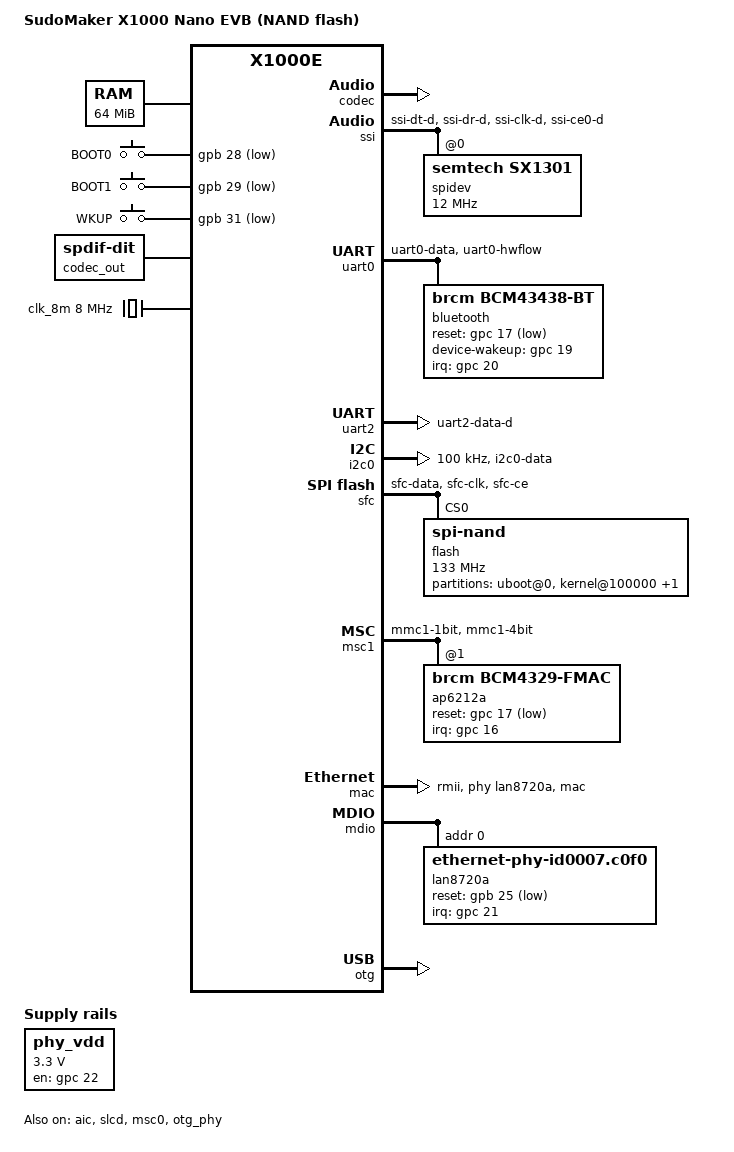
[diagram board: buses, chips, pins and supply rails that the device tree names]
// SPDX-License-Identifier: GPL-2.0
/dts-v1/;

#include "x1000.dtsi"
#include <dt-bindings/gpio/gpio.h>
#include <dt-bindings/input/input.h>
#include <dt-bindings/clock/ingenic,sysost.h>
#include <dt-bindings/interrupt-controller/irq.h>

/ {
	compatible = "sudomaker,x1000-nano-evb", "ingenic,x1000e";
	model = "SudoMaker X1000 Nano EVB (NAND flash)";

	aliases {
		serial2 = &uart2;
	};

	chosen {
		stdout-path = "serial2:115200n8";
	};

	memory {
		device_type = "memory";
		reg = <0x0 0x04000000>;
	};

	gpio_keys {
		compatible = "gpio-keys";

		btn_lf {
			wakeup-source;
			label = "BOOT0";
			linux,code = <KEY_F1>;
			gpios = <&gpb 28 GPIO_ACTIVE_LOW>;
		};

		btn_rf {
			wakeup-source;
			label = "BOOT1";
			linux,code = <KEY_F2>;
			gpios = <&gpb 29 GPIO_ACTIVE_LOW>;
		};

		btn_wkup {
			wakeup-source;
			label = "WKUP";
			linux,code = <KEY_F3>;
			gpios = <&gpb 31 GPIO_ACTIVE_LOW>;
		};
	};

	phy_vdd: regulator-phy_vdd {
				compatible = "regulator-fixed";

				regulator-name = "phy_vdd";
				regulator-min-microvolt = <3300000>;
				regulator-max-microvolt = <3300000>;

				gpio = <&gpc 22 GPIO_ACTIVE_HIGH>;
				enable-active-high;
				regulator-always-on;
	};

	sound {
		compatible = "simple-audio-card";

		simple-audio-card,name = "x1000-aic";

		status = "okay";

		simple-audio-card,bitclock-master = <&dai_codec>;
		simple-audio-card,frame-master = <&dai_codec>;

		simple-audio-card,format = "i2s";

		dai_cpu: simple-audio-card,cpu {
			sound-dai = <&aic>;
			system-clock-frequency = <24000000>;
			system-clock-direction-out;
		};

		dai_codec: simple-audio-card,codec {
			sound-dai = <&codec>;
			system-clock-frequency = <24000000>;
		};
	};

	codec_out: i2s-generic {
				#address-cells = <0>;
				#size-cells = <0>;
				#sound-dai-cells = <0>;
				compatible = "linux,spdif-dit";
				status = "okay";
	};

	clk_8m: clock {
		compatible = "fixed-clock";
		#clock-cells = <0>;
		clock-frequency = <8000000>;
		clock-accuracy = <100>;
	};
};

&exclk {
	clock-frequency = <24000000>;
};

&cgu {
	assigned-clocks = <&cgu X1000_CLK_SSIMUX>, <&cgu X1000_CLK_RTC>;
	assigned-clock-parents = <&cgu X1000_CLK_SSIPLL_DIV2>, <&cgu X1000_CLK_EXCLK_DIV512>;
};

&ost {
	/* 1500 kHz for the system timer and clocksource */
	assigned-clocks = <&ost OST_CLK_EVENT_TIMER>, <&ost OST_CLK_GLOBAL_TIMER>;
	assigned-clock-rates = <1500000>, <1500000>;
};

&aic {
	status = "okay";
	pinctrl-names = "default";
	pinctrl-0 = <&pins_i2s>;

	use-internal-codec;
};

&codec {
	status = "okay";
};

&slcd {
	status = "okay";

	pinctrl-names = "default";
	pinctrl-0 = <&pins_slcd>;

	reset-gpios = <&gpc 25 GPIO_ACTIVE_LOW>;
	rd-gpios = <&gpb 16 GPIO_ACTIVE_LOW>;

	width = <480>;
	height = <800>;
	buswidth = <8>;
	bpp = <24>;
	bus-max-speed = <50000000>;

	sequence-format = <1>; // NT35510: 16bit to 2x8bit, big endian

	init-sequence = /bits/ 16 <
		1 0xf000 2 0x0055
		1 0xf001 2 0x00aa
		1 0xf002 2 0x0052
		1 0xf003 2 0x0008
		1 0xf004 2 0x0001

		1 0xbc01 2 0x0086
		1 0xbc02 2 0x006a
		1 0xbd01 2 0x0086
		1 0xbd02 2 0x006a
		1 0xbe01 2 0x0067

		1 0xd100 2 0x0000
		1 0xd101 2 0x005d
		1 0xd102 2 0x0000
		1 0xd103 2 0x006b
		1 0xd104 2 0x0000
		1 0xd105 2 0x0084
		1 0xd106 2 0x0000
		1 0xd107 2 0x009c
		1 0xd108 2 0x0000
		1 0xd109 2 0x00b1
		1 0xd10a 2 0x0000
		1 0xd10b 2 0x00d9
		1 0xd10c 2 0x0000
		1 0xd10d 2 0x00fd
		1 0xd10e 2 0x0001
		1 0xd10f 2 0x0038
		1 0xd110 2 0x0001
		1 0xd111 2 0x0068
		1 0xd112 2 0x0001
		1 0xd113 2 0x00b9
		1 0xd114 2 0x0001
		1 0xd115 2 0x00fb
		1 0xd116 2 0x0002
		1 0xd117 2 0x0063
		1 0xd118 2 0x0002
		1 0xd119 2 0x00b9
		1 0xd11a 2 0x0002
		1 0xd11b 2 0x00bb
		1 0xd11c 2 0x0003
		1 0xd11d 2 0x0003
		1 0xd11e 2 0x0003
		1 0xd11f 2 0x0046
		1 0xd120 2 0x0003
		1 0xd121 2 0x0069
		1 0xd122 2 0x0003
		1 0xd123 2 0x008f
		1 0xd124 2 0x0003
		1 0xd125 2 0x00a4
		1 0xd126 2 0x0003
		1 0xd127 2 0x00b9
		1 0xd128 2 0x0003
		1 0xd129 2 0x00c7
		1 0xd12a 2 0x0003
		1 0xd12b 2 0x00c9
		1 0xd12c 2 0x0003
		1 0xd12d 2 0x00cb
		1 0xd12e 2 0x0003
		1 0xd12f 2 0x00cb
		1 0xd130 2 0x0003
		1 0xd131 2 0x00cb
		1 0xd132 2 0x0003
		1 0xd133 2 0x00cc

		1 0xd200 2 0x0000
		1 0xd201 2 0x005d
		1 0xd202 2 0x0000
		1 0xd203 2 0x006b
		1 0xd204 2 0x0000
		1 0xd205 2 0x0084
		1 0xd206 2 0x0000
		1 0xd207 2 0x009c
		1 0xd208 2 0x0000
		1 0xd209 2 0x00b1
		1 0xd20a 2 0x0000
		1 0xd20b 2 0x00d9
		1 0xd20c 2 0x0000
		1 0xd20d 2 0x00fd
		1 0xd20e 2 0x0001
		1 0xd20f 2 0x0038
		1 0xd210 2 0x0001
		1 0xd211 2 0x0068
		1 0xd212 2 0x0001
		1 0xd213 2 0x00b9
		1 0xd214 2 0x0001
		1 0xd215 2 0x00fb
		1 0xd216 2 0x0002
		1 0xd217 2 0x0063
		1 0xd218 2 0x0002
		1 0xd219 2 0x00b9
		1 0xd21a 2 0x0002
		1 0xd21b 2 0x00bb
		1 0xd21c 2 0x0003
		1 0xd21d 2 0x0003
		1 0xd21e 2 0x0003
		1 0xd21f 2 0x0046
		1 0xd220 2 0x0003
		1 0xd221 2 0x0069
		1 0xd222 2 0x0003
		1 0xd223 2 0x008f
		1 0xd224 2 0x0003
		1 0xd225 2 0x00a4
		1 0xd226 2 0x0003
		1 0xd227 2 0x00b9
		1 0xd228 2 0x0003
		1 0xd229 2 0x00c7
		1 0xd22a 2 0x0003
		1 0xd22b 2 0x00c9
		1 0xd22c 2 0x0003
		1 0xd22d 2 0x00cb
		1 0xd22e 2 0x0003
		1 0xd22f 2 0x00cb
		1 0xd230 2 0x0003
		1 0xd231 2 0x00cb
		1 0xd232 2 0x0003
		1 0xd233 2 0x00cc

		1 0xd300 2 0x0000
		1 0xd301 2 0x005d
		1 0xd302 2 0x0000
		1 0xd303 2 0x006b
		1 0xd304 2 0x0000
		1 0xd305 2 0x0084
		1 0xd306 2 0x0000
		1 0xd307 2 0x009c
		1 0xd308 2 0x0000
		1 0xd309 2 0x00b1
		1 0xd30a 2 0x0000
		1 0xd30b 2 0x00d9
		1 0xd30c 2 0x0000
		1 0xd30d 2 0x00fd
		1 0xd30e 2 0x0001
		1 0xd30f 2 0x0038
		1 0xd310 2 0x0001
		1 0xd311 2 0x0068
		1 0xd312 2 0x0001
		1 0xd313 2 0x00b9
		1 0xd314 2 0x0001
		1 0xd315 2 0x00fb
		1 0xd316 2 0x0002
		1 0xd317 2 0x0063
		1 0xd318 2 0x0002
		1 0xd319 2 0x00b9
		1 0xd31a 2 0x0002
		1 0xd31b 2 0x00bb
		1 0xd31c 2 0x0003
		1 0xd31d 2 0x0003
		1 0xd31e 2 0x0003
		1 0xd31f 2 0x0046
		1 0xd320 2 0x0003
		1 0xd321 2 0x0069
		1 0xd322 2 0x0003
		1 0xd323 2 0x008f
		1 0xd324 2 0x0003
		1 0xd325 2 0x00a4
		1 0xd326 2 0x0003
		1 0xd327 2 0x00b9
		1 0xd328 2 0x0003
		1 0xd329 2 0x00c7
		1 0xd32a 2 0x0003
		1 0xd32b 2 0x00c9
		1 0xd32c 2 0x0003
		1 0xd32d 2 0x00cb
		1 0xd32e 2 0x0003
		1 0xd32f 2 0x00cb
		1 0xd330 2 0x0003
		1 0xd331 2 0x00cb
		1 0xd332 2 0x0003
		1 0xd333 2 0x00cc

		1 0xd400 2 0x0000
		1 0xd401 2 0x005d
		1 0xd402 2 0x0000
		1 0xd403 2 0x006b
		1 0xd404 2 0x0000
		1 0xd405 2 0x0084
		1 0xd406 2 0x0000
		1 0xd407 2 0x009c
		1 0xd408 2 0x0000
		1 0xd409 2 0x00b1
		1 0xd40a 2 0x0000
		1 0xd40b 2 0x00d9
		1 0xd40c 2 0x0000
		1 0xd40d 2 0x00fd
		1 0xd40e 2 0x0001
		1 0xd40f 2 0x0038
		1 0xd410 2 0x0001
		1 0xd411 2 0x0068
		1 0xd412 2 0x0001
		1 0xd413 2 0x00b9
		1 0xd414 2 0x0001
		1 0xd415 2 0x00fb
		1 0xd416 2 0x0002
		1 0xd417 2 0x0063
		1 0xd418 2 0x0002
		1 0xd419 2 0x00b9
		1 0xd41a 2 0x0002
		1 0xd41b 2 0x00bb
		1 0xd41c 2 0x0003
		1 0xd41d 2 0x0003
		1 0xd41e 2 0x0003
		1 0xd41f 2 0x0046
		1 0xd420 2 0x0003
		1 0xd421 2 0x0069
		1 0xd422 2 0x0003
		1 0xd423 2 0x008f
		1 0xd424 2 0x0003
		1 0xd425 2 0x00a4
		1 0xd426 2 0x0003
		1 0xd427 2 0x00b9
		1 0xd428 2 0x0003
		1 0xd429 2 0x00c7
		1 0xd42a 2 0x0003
		1 0xd42b 2 0x00c9
		1 0xd42c 2 0x0003
		1 0xd42d 2 0x00cb
		1 0xd42e 2 0x0003
		1 0xd42f 2 0x00cb
		1 0xd430 2 0x0003
		1 0xd431 2 0x00cb
		1 0xd432 2 0x0003
		1 0xd433 2 0x00cc

		1 0xd500 2 0x0000
		1 0xd501 2 0x005d
		1 0xd502 2 0x0000
		1 0xd503 2 0x006b
		1 0xd504 2 0x0000
		1 0xd505 2 0x0084
		1 0xd506 2 0x0000
		1 0xd507 2 0x009c
		1 0xd508 2 0x0000
		1 0xd509 2 0x00b1
		1 0xd50a 2 0x0000
		1 0xd50b 2 0x00D9
		1 0xd50c 2 0x0000
		1 0xd50d 2 0x00fd
		1 0xd50e 2 0x0001
		1 0xd50f 2 0x0038
		1 0xd510 2 0x0001
		1 0xd511 2 0x0068
		1 0xd512 2 0x0001
		1 0xd513 2 0x00b9
		1 0xd514 2 0x0001
		1 0xd515 2 0x00fb
		1 0xd516 2 0x0002
		1 0xd517 2 0x0063
		1 0xd518 2 0x0002
		1 0xd519 2 0x00b9
		1 0xd51a 2 0x0002
		1 0xd51b 2 0x00bb
		1 0xd51c 2 0x0003
		1 0xd51d 2 0x0003
		1 0xd51e 2 0x0003
		1 0xd51f 2 0x0046
		1 0xd520 2 0x0003
		1 0xd521 2 0x0069
		1 0xd522 2 0x0003
		1 0xd523 2 0x008f
		1 0xd524 2 0x0003
		1 0xd525 2 0x00a4
		1 0xd526 2 0x0003
		1 0xd527 2 0x00b9
		1 0xd528 2 0x0003
		1 0xd529 2 0x00c7
		1 0xd52a 2 0x0003
		1 0xd52b 2 0x00c9
		1 0xd52c 2 0x0003
		1 0xd52d 2 0x00cb
		1 0xd52e 2 0x0003
		1 0xd52f 2 0x00cb
		1 0xd530 2 0x0003
		1 0xd531 2 0x00cb
		1 0xd532 2 0x0003
		1 0xd533 2 0x00cc

		1 0xd600 2 0x0000
		1 0xd601 2 0x005d
		1 0xd602 2 0x0000
		1 0xd603 2 0x006b
		1 0xd604 2 0x0000
		1 0xd605 2 0x0084
		1 0xd606 2 0x0000
		1 0xd607 2 0x009c
		1 0xd608 2 0x0000
		1 0xd609 2 0x00b1
		1 0xd60a 2 0x0000
		1 0xd60b 2 0x00d9
		1 0xd60c 2 0x0000
		1 0xd60d 2 0x00fd
		1 0xd60e 2 0x0001
		1 0xd60f 2 0x0038
		1 0xd610 2 0x0001
		1 0xd611 2 0x0068
		1 0xd612 2 0x0001
		1 0xd613 2 0x00b9
		1 0xd614 2 0x0001
		1 0xd615 2 0x00fb
		1 0xd616 2 0x0002
		1 0xd617 2 0x0063
		1 0xd618 2 0x0002
		1 0xd619 2 0x00b9
		1 0xd61a 2 0x0002
		1 0xd61b 2 0x00bb
		1 0xd61c 2 0x0003
		1 0xd61d 2 0x0003
		1 0xd61e 2 0x0003
		1 0xd61f 2 0x0046
		1 0xd620 2 0x0003
		1 0xd621 2 0x0069
		1 0xd622 2 0x0003
		1 0xd623 2 0x008f
		1 0xd624 2 0x0003
		1 0xd625 2 0x00a4
		1 0xd626 2 0x0003
		1 0xd627 2 0x00b9
		1 0xd628 2 0x0003
		1 0xd629 2 0x00c7
		1 0xd62a 2 0x0003
		1 0xd62b 2 0x00c9
		1 0xd62c 2 0x0003
		1 0xd62d 2 0x00cb
		1 0xd62e 2 0x0003
		1 0xd62f 2 0x00cb
		1 0xd630 2 0x0003
		1 0xd631 2 0x00cb
		1 0xd632 2 0x0003
		1 0xd633 2 0x00cc

		1 0xba00 2 0x0024
		1 0xba01 2 0x0024
		1 0xba02 2 0x0024

		1 0xb900 2 0x0024
		1 0xb901 2 0x0024
		1 0xb902 2 0x0024

		1 0xf000 2 0x0055
		1 0xf001 2 0x00aa
		1 0xf002 2 0x0052
		1 0xf003 2 0x0008
		1 0xf004 2 0x0000

		1 0xb100 2 0x00cc

		1 0xbc00 2 0x0005
		1 0xbc01 2 0x0005
		1 0xbc02 2 0x0005

		1 0xb800 2 0x0001
		1 0xb801 2 0x0003
		1 0xb802 2 0x0003
		1 0xb803 2 0x0003

		1 0xbd02 2 0x0007
		1 0xbd03 2 0x0031
		1 0xbe02 2 0x0007
		1 0xbe03 2 0x0031
		1 0xbf02 2 0x0007
		1 0xbf03 2 0x0031

		1 0xff00 2 0x00aa
		1 0xff01 2 0x0055
		1 0xff02 2 0x0025
		1 0xff03 2 0x0001

		1 0xf304 2 0x0011
		1 0xf306 2 0x0010
		1 0xf308 2 0x0000

		1 0x3500 2 0x0000

		1 0x2a00 2 0x0000
		1 0x2a01 2 0x0000
		1 0x2a02 2 0x0001
		1 0x2a03 2 0x00df

		1 0x2b00 2 0x0000
		1 0x2b01 2 0x0000
		1 0x2b02 2 0x0003
		1 0x2b03 2 0x001f
		1 0x3600 2 0x00c0

		1 0x1100
		3 50

		1 0x2900
		1 0x2c00 2 0x0000 2 0x0000 2 0x0000
	>;

	write-sequence = /bits/ 16 <
		1 0x2c00
	>;

	window-sequence = /bits/ 16 <
		1 0x2a00 4 0
		1 0x2a01 4 1
		1 0x2a02 4 2
		1 0x2a03 4 3

		1 0x2b00 4 4
		1 0x2b01 4 5
		1 0x2b02 4 6
		1 0x2b03 4 7
	>;

	rotate-sequence-0 = /bits/ 16 <
		1 0x3600 2 0x0000
	>;

	rotate-sequence-90 = /bits/ 16 <
		1 0x3600 2 0x0060
	>;

	rotate-sequence-180 = /bits/ 16 <
		1 0x3600 2 0x00c0
	>;

	rotate-sequence-270 = /bits/ 16 <
		1 0x3600 2 0x00a0
	>;
};

&ssi {
	status = "okay";

	pinctrl-names = "default";
	pinctrl-0 = <&pins_spi0>;

	num-cs = <1>;
	cs-gpios = <0>;

	spidev: spidev@0 {
		reg = <0>;
		compatible = "semtech,sx1301";

		spi-max-frequency = <12000000>;
	};

};

&uart0 {
		status = "okay";

		pinctrl-names = "default";
		pinctrl-0 = <&pins_uart0>;

		uart-has-rtscts;

		bluetooth {
				compatible = "brcm,bcm43438-bt";
				max-speed = <1000000>;
				brcm,bt-pcm-int-params = [01 02 00 01 01];
				reset-gpios = <&gpc 17 GPIO_ACTIVE_LOW>;
				device-wakeup-gpios = <&gpc 19 GPIO_ACTIVE_HIGH>;
				interrupt-parent = <&gpc>;
				interrupts = <20 IRQ_TYPE_EDGE_FALLING>;
		};
};

&uart2 {
	status = "okay";

	pinctrl-names = "default";
	pinctrl-0 = <&pins_uart2>;
};

&i2c0 {
	status = "okay";

	clock-frequency = <100000>;

	pinctrl-names = "default";
	pinctrl-0 = <&pins_i2c0>;
};


&sfc {
	status = "okay";

	#address-cells = <1>;
	#size-cells = <0>;


	pinctrl-names = "default";
	pinctrl-0 = <&pins_sfc>;

	flash: spinand@0 {
		compatible = "spi-nand";
		spi-max-frequency = <133000000>;
		reg = <0>;

		spi-rx-bus-width = <4>;
		spi-tx-bus-width = <4>;

		partitions {
			compatible = "fixed-partitions";
			#address-cells = <1>;
			#size-cells = <1>;

			uboot@0 {
				reg = <0x0 0x100000>;
			};

			kernel@100000 {
				reg = <0x100000 0x400000>;
				read-only;
			};

			rootfs@500000 {
				reg = <0x500000 0xFB00000>;
			};
		};
	};

};

&msc0 {
	status = "okay";

	bus-width = <4>;
	max-frequency = <50000000>;

	pinctrl-names = "default";
	pinctrl-0 = <&pins_msc0>;

	non-removable;
};

&msc1 {
		status = "okay";

		#address-cells = <1>;
		#size-cells = <0>;
		bus-width = <4>;
		max-frequency = <25000000>;

		pinctrl-names = "default";
		pinctrl-0 = <&pins_msc1>;

		non-removable;
		cap-power-off-card;
		keep-power-in-suspend;
		wakeup-source;

		//mmc-pwrseq = <&wlan_pwrseq>;

		ap6212a: wifi@1 {
				compatible = "brcm,bcm4329-fmac";
				reg = <1>;

				interrupt-parent = <&gpc>;
				interrupts = <16 IRQ_TYPE_EDGE_FALLING>;
				interrupt-names = "host-wake";
				wakeup-source;

				reset-gpios = <&gpc 17 GPIO_ACTIVE_LOW>;

				brcm,drive-strength = <10>;
		};
};

&mac {
	status = "okay";

	phy-mode = "rmii";
	phy-handle = <&lan8720a>;

	pinctrl-names = "default";
	pinctrl-0 = <&pins_mac>;
};

&mdio {
	status = "okay";

	lan8720a: ethernet-phy@0 {
		compatible = "ethernet-phy-id0007.c0f0", "ethernet-phy-ieee802.3-c22";
		reg = <0>;

		interrupt-parent = <&gpc>;
		interrupts = <21 IRQ_TYPE_LEVEL_LOW>;
		wakeup-source;

		reset-names = "phy";
		reset-gpios = <&gpb 25 GPIO_ACTIVE_LOW>;
		reset-assert-us = <10000>;
		reset-deassert-us = <30000>;
	};
};

&otg_phy {
	status = "okay";
};

&otg {
	status = "okay";
};

&pinctrl {

	pins_sfc: sfc {
		function = "sfc";
		groups = "sfc-data", "sfc-clk", "sfc-ce";
	};

	pins_slcd: slcd {
		function = "lcd";
		groups = "lcd-8bit";
	};

	pins_spi0: spi0 {
			function = "ssi";
			groups = "ssi-dt-d", "ssi-dr-d", "ssi-clk-d", "ssi-ce0-d";
	};

	pins_uart0: uart0 {
		function = "uart0";
		groups = "uart0-data", "uart0-hwflow";
	};

	pins_uart2: uart2 {
		function = "uart2";
		groups = "uart2-data-d";
	};

	pins_i2c0: i2c0 {
		function = "i2c0";
		groups = "i2c0-data";
		bias-disable;
	};

	pins_i2s: i2s {
		function = "i2s";
		groups = "i2s-data-tx", "i2s-data-rx", "i2s-clk-txrx", "i2s-sysclk";
	};

	pins_msc0: msc0 {
		function = "mmc0";
		groups = "mmc0-1bit", "mmc0-4bit";
	};

	pins_msc1: msc1 {
		function = "mmc1";
		groups = "mmc1-1bit", "mmc1-4bit";
	};

	pins_mac: mac {
		function = "mac";
		groups = "mac";
		bias-disable;
	};
};
